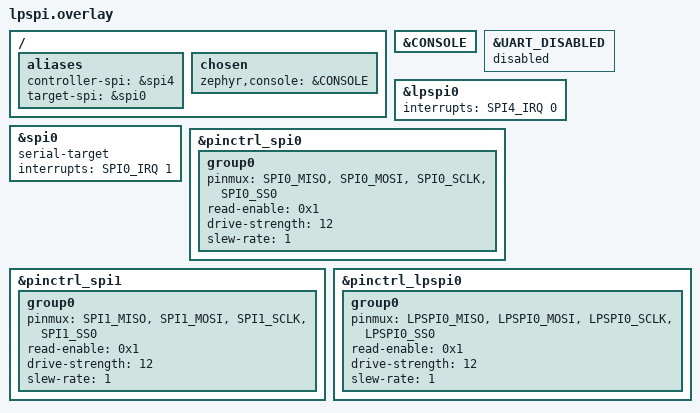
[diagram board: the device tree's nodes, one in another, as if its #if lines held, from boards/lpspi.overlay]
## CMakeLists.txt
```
cmake_minimum_required(VERSION 3.20.0)

# ==================== BOARD OVERRIDE (optional) ==================
# ALIF_BOARD is auto-detected in board_common.overlay from Zephyr
# Kconfig symbols (CONFIG_SOC_SERIES_* / CONFIG_RTSS_*).
# To override manually: west build -b <board> -- -DALIF_BOARD=ALIF_BOARD_E7_HP
if(DEFINED ALIF_BOARD)
  list(APPEND DTS_EXTRA_CPPFLAGS "-DALIF_BOARD=${ALIF_BOARD}")
  message(STATUS "SPI test overlay board (manual override): ${ALIF_BOARD}")
endif()

# ==================== ZEPHYR PROJECT SETUP ==================
find_package(Zephyr REQUIRED HINTS $ENV{ZEPHYR_BASE})
project(alif_spi)

# ==================== STACK SIZES ==========================
# Stack sizes are defined in prj.conf (20KB default for all tests)

target_include_directories(app PRIVATE src)

# ==================== SOURCE FILES ==========================
target_sources(app PRIVATE
  src/test_spi_common.c
  src/test_spi_threads.c
)

target_sources_ifdef(CONFIG_TEST_SPI_LOOPBACK    app PRIVATE src/test_spi_loopback.c)
target_sources_ifdef(CONFIG_TEST_SPI_NEGATIVE   app PRIVATE src/test_spi_negative.c)
target_sources_ifdef(CONFIG_TEST_SPI_BOUNDARY   app PRIVATE src/test_spi_boundary.c)
target_sources_ifdef(CONFIG_TEST_SPI_STRESS     app PRIVATE src/test_spi_stress.c)
target_sources_ifdef(CONFIG_TEST_SPI_PERFORMANCE app PRIVATE src/test_spi_perf.c)

# ==================== COMPILATION FLAGS ======================
if(CMAKE_BUILD_TYPE STREQUAL "Debug")
  target_compile_options(app PRIVATE -Wall -Wextra -Werror)
endif()

# ==================== VALIDATION MESSAGES ====================
message(STATUS "  Test Type: SPI Driver Validation")
message(STATUS "  Hardware Overlay: ${DTC_OVERLAY_FILE}")

if(CONFIG_TEST_SPI_LOOPBACK)
  message(STATUS "  Enabled: Loopback Tests")
endif()

if(CONFIG_TEST_SPI_NEGATIVE)
  message(STATUS "  Enabled: Negative Tests")
endif()

if(CONFIG_TEST_SPI_BOUNDARY)
  message(STATUS "  Enabled: Boundary Tests")
endif()

if(CONFIG_TEST_SPI_STRESS)
  message(STATUS "  Enabled: Stress Tests")
endif()

if(CONFIG_TEST_SPI_PERFORMANCE)
  message(STATUS "  Enabled: Performance Tests")
endif()

if(CONFIG_TEST_SPI_USE_DMA)
  message(STATUS "  Enabled: DMA path")
endif()
```

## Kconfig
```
source "Kconfig.zephyr"

# ---------------------------------------------------------------------------
# Test selection - enable the test you want to run
# ---------------------------------------------------------------------------

config TEST_SPI_LOOPBACK
	bool "Loopback tests"
	help
	  Enable the SPI loopback test suite.  This suite exercises
	  the controller by wiring MOSI to MISO either internally or
	  externally and validates data integrity across 8, 16 and
	  32-bit word sizes at configurable frequencies.

config TEST_SPI_NEGATIVE
	bool "Negative tests"
	help
	  Enable the SPI negative test suite.  These tests deliberately
	  pass invalid configurations, unsupported SPI modes, and null
	  pointers to the driver to verify that proper error codes are
	  returned and the driver does not crash or corrupt state.

config TEST_SPI_BOUNDARY
	bool "Boundary tests"
	help
	  Enable the SPI boundary test suite.  These tests probe driver
	  behaviour at FIFO depth limits, minimum and maximum transfer
	  sizes, unaligned buffer addresses, and extreme word widths
	  to ensure robust handling of edge cases.

config TEST_SPI_STRESS
	bool "Stress tests"
	help
	  SPI stress tests that exercise repeated back-to-back
	  full-duplex transfers between two controllers (SPI1 <-> SPI0)
	  with rotating data patterns. Detects FIFO leakage and
	  state retention issues across iterations.

config TEST_SPI_PERFORMANCE
	bool "Performance tests"
	help
	  Enable the SPI performance test suite.  It runs back-to-back
	  MOSI, MISO and full-duplex transceive tests while sweeping the
	  frequency from TEST_SPI_PERF_FREQ_MIN_MHZ to
	  TEST_SPI_PERF_FREQ_MAX_MHZ (defaults 1x..50x the base rate) in
	  TEST_SPI_PERF_FREQ_STEP_MHZ increments, reporting cycle counts
	  and elapsed time.

# ---------------------------------------------------------------------------
# Performance sweep range (multipliers of TEST_SPI_FREQUENCY)
# ---------------------------------------------------------------------------

config TEST_SPI_PERF_FREQ_MIN_MHZ
	int "Performance sweep start frequency (x base)"
	depends on TEST_SPI_PERFORMANCE
	default 1
	help
	  First frequency multiplier of the performance sweep, in units
	  of TEST_SPI_FREQUENCY (default base 1 MHz).  With the default
	  base of 1 MHz this is the start frequency in MHz.

config TEST_SPI_PERF_FREQ_MAX_MHZ
	int "Performance sweep end frequency (x base)"
	depends on TEST_SPI_PERFORMANCE
	default 5
	help
	  Last frequency multiplier of the performance sweep, in units
	  of TEST_SPI_FREQUENCY (default base 1 MHz).  With the default
	  base of 1 MHz this is the end frequency in MHz.

config TEST_SPI_PERF_FREQ_STEP_MHZ
	int "Performance sweep step (x base)"
	depends on TEST_SPI_PERFORMANCE
	range 1 5
	default 1
	help
	  Increment between consecutive sweep points, in units of
	  TEST_SPI_FREQUENCY.  The endpoint TEST_SPI_PERF_FREQ_MAX_MHZ is
	  always tested even if it does not fall on a step boundary.

# ---------------------------------------------------------------------------
# Test options
# ---------------------------------------------------------------------------

config TEST_SPI_INTERNAL_LOOPBACK
	bool "Use controller internal loopback for loopback and boundary tests"
	depends on TEST_SPI_LOOPBACK || TEST_SPI_BOUNDARY
	default y
	help
	  When enabled, loopback and boundary tests run on a single
	  controller using the SPI_MODE_LOOP flag (no external wiring
	  needed). When disabled, the same tests run across two
	  controllers (SPI1 as controller, SPI0 as target wired
	  together) and validate both MOSI and MISO directions
	  with two independent transceives.

config TEST_SPI_WORD_SIZE
	int "SPI word size for all tests"
	range 4 32
	default 8
	help
	  Fixed word size (4..32 bits) used by all test suites.

config TEST_SPI_FREQUENCY
	int "SPI test base frequency (Hz)"
	default 1000000
	help
	  Base operating frequency used by all SPI test scenarios.
	  Frequency sweep multipliers (1x, 5x, 12x, 25x) and the
	  performance sweep are relative to this value.  Default is
	  1 MHz (1000000 Hz).

# ---------------------------------------------------------------------------
# DMA support
# ---------------------------------------------------------------------------
config TEST_SPI_USE_DMA
	bool "Enable DMA for SPI transfers"
	depends on $(dt_nodelabel_enabled,dma0) || $(dt_nodelabel_enabled,dma1) || $(dt_nodelabel_enabled,dma2)
	select SPI_DW_USE_DMA
	select DMA
	select DMA_PL330
	help
	  Enable DMA-based SPI transfers for all selected test suites.
	  When enabled, the driver routes large transfers through the
	  PL330 DMA controller instead of the PIO path.  This option is
	  only selectable when a DMA controller node is present in the
	  active devicetree overlay (e.g. spi_DMA.overlay).
```

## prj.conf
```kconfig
# Note: SPI slave mode (target role) enabled
# Base SPI driver
CONFIG_SPI=y
CONFIG_SPI_DW=y
CONFIG_SPI_SLAVE=y

# Zephyr test framework
CONFIG_ZTEST=y


CONFIG_LOG=y
CONFIG_LOG_DEFAULT_LEVEL=1

# Kernel features
CONFIG_EVENTS=y
CONFIG_STDOUT_CONSOLE=y

# Async SPI path coverage (sync path uses spi_transceive, async uses
# spi_transceive_signal which needs both of these)
CONFIG_SPI_ASYNC=y
CONFIG_POLL=y

# Stack sizes - stress tests need larger stacks
CONFIG_MAIN_STACK_SIZE=20480
CONFIG_ZTEST_STACK_SIZE=20480
```

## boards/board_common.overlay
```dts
/* Copyright (C) 2025 Alif Semiconductor - All Rights Reserved.
 * Use, distribution and modification of this code is permitted under the
 * terms stated in the Alif Semiconductor Software License Agreement
 *
 * You should have received a copy of the Alif Semiconductor Software
 * License Agreement with this file. If not, please write to:
 * contact@alifsemi.com, or visit: https://alifsemi.com/license
 */

/*
 * -----------------------------------------------------------------------
 * Alif SPI test board-common macros.
 *
 * Include this from every instance/feature overlay:
 *   #include "board_common.overlay"
 *
 * It defines board-specific pinmux, interrupt numbers, GPIO/SS mappings,
 * console choice and DMA controller — everything that varies by board.
 *
 * Instance overlays then only need to:
 *   - pick controller-spi / target-spi aliases
 *   - &node { status = "okay"; interrupts = <ALIF_SPIx_IRQ 0>; };
 *   - apply &pinctrl using the ALIF_SPIx_* macros from this file.
 * -----------------------------------------------------------------------
 */

#ifndef ALIF_BOARD_COMMON_OVERLAY
#define ALIF_BOARD_COMMON_OVERLAY

/* --- Board enum ------------------------------------------------------- */
#define ALIF_BOARD_E7_HP 1
#define ALIF_BOARD_E8_HP 2
#define ALIF_BOARD_E7_HE 3
#define ALIF_BOARD_E8_HE 4
#define ALIF_BOARD_E1C   5
#define ALIF_BOARD_B1    6

/* Manual override: -DALIF_BOARD=ALIF_BOARD_E7_HP on west command line  */
#ifndef ALIF_BOARD
#define ALIF_BOARD ALIF_BOARD_E8_HP
#endif

/* --- Console (UART) --------------------------------------------------- */
#if ALIF_BOARD == ALIF_BOARD_E7_HP || ALIF_BOARD == ALIF_BOARD_E8_HP
  #define CONSOLE          uart4
  #define UART_DISABLED    uart2
#else
  #define CONSOLE          lpuart
  #define UART_DISABLED    uart2
#endif

/* --- SPI0 pinmux ------------------------------------------------------ */
#if ALIF_BOARD == ALIF_BOARD_E1C || ALIF_BOARD == ALIF_BOARD_B1
  #define SPI0_MISO   PIN_P5_0__SPI0_MISO_B
  #define SPI0_MOSI   PIN_P5_1__SPI0_MOSI_B
  #define SPI0_SCLK   PIN_P5_2__SPI0_SCLK_B
  #define SPI0_SS0    PIN_P5_3__SPI0_SS0_B
#elif ALIF_BOARD == ALIF_BOARD_E7_HP || ALIF_BOARD == ALIF_BOARD_E7_HE
  #define SPI0_MISO   PIN_P5_0__SPI0_MISO_B
  #define SPI0_MOSI   PIN_P5_1__SPI0_MOSI_B
  #define SPI0_SCLK   PIN_P5_3__SPI0_SCLK_B
  #define SPI0_SS0    PIN_P5_2__SPI0_SS0_B
#else
  #define SPI0_MISO   PIN_P1_0__SPI0_MISO_A
  #define SPI0_MOSI   PIN_P1_1__SPI0_MOSI_A
  #define SPI0_SCLK   PIN_P1_2__SPI0_SCLK_A
  #define SPI0_SS0    PIN_P1_3__SPI0_SS0_A
#endif

/* --- SPI1 pinmux ------------------------------------------------------ */
#if ALIF_BOARD == ALIF_BOARD_E7_HP || ALIF_BOARD == ALIF_BOARD_E7_HE
  #define SPI1_MISO   PIN_P8_3__SPI1_MISO_B
  #define SPI1_MOSI   PIN_P8_4__SPI1_MOSI_B
  #define SPI1_SCLK   PIN_P8_5__SPI1_SCLK_B
  #define SPI1_SS0    PIN_P6_4__SPI1_SS0_B
#elif ALIF_BOARD == ALIF_BOARD_E8_HP || ALIF_BOARD == ALIF_BOARD_E8_HE
  #define SPI1_MISO   PIN_P14_4__SPI1_MISO_C
  #define SPI1_MOSI   PIN_P14_5__SPI1_MOSI_C
  #define SPI1_SCLK   PIN_P14_6__SPI1_SCLK_C
  #define SPI1_SS0    PIN_P14_7__SPI1_SS0_C
#elif ALIF_BOARD == ALIF_BOARD_E1C || ALIF_BOARD == ALIF_BOARD_B1
  #define SPI1_MISO   PIN_P8_4__SPI1_MISO_C
  #define SPI1_MOSI   PIN_P8_5__SPI1_MOSI_C
  #define SPI1_SCLK   PIN_P8_6__SPI1_SCLK_C
  #define SPI1_SS0    PIN_P8_7__SPI1_SS0_C
#endif

/* --- SPI2 pinmux ------------------------------------------------------ */
#if ALIF_BOARD == ALIF_BOARD_E1C || ALIF_BOARD == ALIF_BOARD_B1
  #define SPI2_MISO   PIN_P7_0__SPI2_MISO_B
  #define SPI2_MOSI   PIN_P7_1__SPI2_MOSI_B
  #define SPI2_SCLK   PIN_P7_2__SPI2_SCLK_B
  #define SPI2_SS0    PIN_P7_3__SPI2_SS0_B
#else
  #define SPI2_MISO   PIN_P4_2__SPI2_MISO_A
  #define SPI2_MOSI   PIN_P4_3__SPI2_MOSI_A
  #define SPI2_SCLK   PIN_P4_4__SPI2_SCLK_A
  #define SPI2_SS0    PIN_P4_5__SPI2_SS0_A
#endif

/* --- SPI3 pinmux ------------------------------------------------------ */
#if ALIF_BOARD == ALIF_BOARD_E7_HP || \
	ALIF_BOARD == ALIF_BOARD_E7_HE
  #define SPI3_MISO   PIN_P10_5__SPI3_MISO_B
  #define SPI3_MOSI   PIN_P12_5__SPI3_MOSI_A
  #define SPI3_SCLK   PIN_P12_6__SPI3_SCLK_B
  #define SPI3_SS0    PIN_P12_7__SPI3_SS0_B
#elif ALIF_BOARD == ALIF_BOARD_E8_HP || \
	ALIF_BOARD == ALIF_BOARD_E8_HE
  #define SPI3_MISO   PIN_P12_4__SPI3_MISO_A
  #define SPI3_MOSI   PIN_P12_5__SPI3_MOSI_A
  #define SPI3_SCLK   PIN_P12_6__SPI3_SCLK_A
  #define SPI3_SS0    PIN_P12_7__SPI3_SS0_A
#endif

/* --- SPI4 / LPSPI0 pinmux (HE boards) -------------------------- */
#if ALIF_BOARD == ALIF_BOARD_E7_HE
  #define SPI4_MISO   PIN_P7_4__LPSPI_MISO_A
  #define SPI4_MOSI   PIN_P7_5__LPSPI_MOSI_A
  #define SPI4_SCLK   PIN_P7_6__LPSPI_SCLK_A
  #define SPI4_SS0    PIN_P7_7__LPSPI_SS_A
#elif ALIF_BOARD == ALIF_BOARD_E8_HE
  #define SPI4_MISO   PIN_P11_4__LPSPI_MISO_B
  #define SPI4_MOSI   PIN_P11_5__LPSPI_MOSI_B
  #define SPI4_SCLK   PIN_P11_6__LPSPI_SCLK_B
  #define SPI4_SS0    PIN_P11_7__LPSPI_SS0_B
#elif ALIF_BOARD == ALIF_BOARD_E1C || ALIF_BOARD == ALIF_BOARD_B1
  #define LPSPI0_MISO PIN_P1_3__LPSPI_MISO_A
  #define LPSPI0_MOSI PIN_P1_4__LPSPI_MOSI_A
  #define LPSPI0_SCLK PIN_P1_5__LPSPI_SCLK_A
  #define LPSPI0_SS0  PIN_P2_0__LPSPI_SS_A
#endif

/* --- Interrupt numbers (instance-based, same across boards) ---------- */
#define SPI0_IRQ    137
#define SPI1_IRQ    138
#define SPI2_IRQ    139
#define SPI3_IRQ    140
#define SPI4_IRQ    46   /* LPSPI0 interrupt number */

/* --- Software-CS GPIO pins (SPI1-based overlays) --------------------- */
#if ALIF_BOARD == ALIF_BOARD_E7_HP || ALIF_BOARD == ALIF_BOARD_E7_HE
  #define SPI_SS_GPIO_PIN   PIN_P6_4__GPIO
  #define SPI_SS_GPIO_BANK  gpio6
  #define SPI_SS_GPIO_NUM   4
#elif ALIF_BOARD == ALIF_BOARD_E8_HP || ALIF_BOARD == ALIF_BOARD_E8_HE
  #define SPI_SS_GPIO_PIN   PIN_P14_7__GPIO
  #define SPI_SS_GPIO_BANK  gpio14
  #define SPI_SS_GPIO_NUM   7
#elif ALIF_BOARD == ALIF_BOARD_E1C || ALIF_BOARD == ALIF_BOARD_B1
  #define SPI_SS_GPIO_PIN   PIN_P8_7__GPIO
  #define SPI_SS_GPIO_BANK  gpio8
  #define SPI_SS_GPIO_NUM   7
#endif

/* --- Software-CS GPIO pins (LPSPI-based overlays) --------------------- */
#if ALIF_BOARD == ALIF_BOARD_E7_HE
  #define LPSPI_SS_GPIO_PIN   PIN_P7_7__GPIO
  #define LPSPI_SS_GPIO_BANK  gpio7
  #define LPSPI_SS_GPIO_NUM   7
#elif ALIF_BOARD == ALIF_BOARD_E8_HE
  #define LPSPI_SS_GPIO_PIN   PIN_P11_7__GPIO
  #define LPSPI_SS_GPIO_BANK  gpio11
  #define LPSPI_SS_GPIO_NUM   7
#elif ALIF_BOARD == ALIF_BOARD_E1C || ALIF_BOARD == ALIF_BOARD_B1
  #define LPSPI_SS_GPIO_PIN   PIN_P2_0__GPIO
  #define LPSPI_SS_GPIO_BANK  gpio2
  #define LPSPI_SS_GPIO_NUM   0
#endif

/* --- DMA controller for SPI0/SPI1 ---------------------------------- */
#if ALIF_BOARD == ALIF_BOARD_E1C || ALIF_BOARD == ALIF_BOARD_B1
  #define SPI_DMA          dma2
  #define SPI_DMA_EVTRTR   evtrtr2
#else
  #define SPI_DMA          dma0
  #define SPI_DMA_EVTRTR   evtrtr0
#endif

#endif /* ALIF_BOARD_COMMON_OVERLAY */
```

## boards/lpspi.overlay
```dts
/* Copyright (C) 2025 Alif Semiconductor - All Rights Reserved.
 * Use, distribution and modification of this code is permitted under the
 * terms stated in the Alif Semiconductor Software License Agreement
 *
 * You should have received a copy of the Alif Semiconductor Software
 * License Agreement with this file. If not, please write to:
 * contact@alifsemi.com, or visit: https://alifsemi.com/license
 */

/* LPSPI / SPI test overlay.
 * HE: SPI4 controller <-> SPI0/SPI1 target (board-dependent)
 * E1C/B1: LPSPI0 controller <-> SPI1 target
 */
#include "board_common.overlay"

/ {
	aliases {
#if ALIF_BOARD == ALIF_BOARD_E7_HE
		controller-spi = &spi4;
		target-spi     = &spi0;
#elif ALIF_BOARD == ALIF_BOARD_E8_HE
		controller-spi = &spi4;
		target-spi     = &spi1;
#elif ALIF_BOARD == ALIF_BOARD_E1C || ALIF_BOARD == ALIF_BOARD_B1
		controller-spi = &lpspi0;
		target-spi     = &spi1;
#else
		/* Default to SPI4/SPI0 for unknown HE boards */
		controller-spi = &spi4;
		target-spi     = &spi0;
#endif
	};

	chosen {
		zephyr,console = &CONSOLE;
	};
};

&CONSOLE {
	status = "okay";
};

&UART_DISABLED {
	status = "disabled";
};

#if ALIF_BOARD == ALIF_BOARD_E1C || ALIF_BOARD == ALIF_BOARD_B1
&lpspi0 {
	status = "okay";
	interrupts = <SPI4_IRQ 0>;
};
#else
&spi4 {
	status = "okay";
	interrupts = <SPI4_IRQ 0>;
};
#endif

#if ALIF_BOARD == ALIF_BOARD_E7_HE
&spi0 {
	status = "okay";
	serial-target;
	interrupts = <SPI0_IRQ 1>;
};
#else
&spi1 {
	status = "okay";
	serial-target;
	interrupts = <SPI1_IRQ 1>;
};
#endif

#if ALIF_BOARD == ALIF_BOARD_E7_HE
&pinctrl_spi0 {
	group0 {
		pinmux = < SPI0_MISO >,
			 < SPI0_MOSI >,
			 < SPI0_SCLK >,
			 < SPI0_SS0 >;
		read-enable = < 0x1 >;
		drive-strength = < 12 >;
		slew-rate = < 1 >;
	};
};
#endif

#if ALIF_BOARD != ALIF_BOARD_E7_HE
&pinctrl_spi1 {
	group0 {
		pinmux = < SPI1_MISO >,
			 < SPI1_MOSI >,
			 < SPI1_SCLK >,
			 < SPI1_SS0 >;
		read-enable = < 0x1 >;
		drive-strength = < 12 >;
		slew-rate = < 1 >;
	};
};
#endif

#if ALIF_BOARD == ALIF_BOARD_E1C || ALIF_BOARD == ALIF_BOARD_B1
&pinctrl_lpspi0 {
	group0 {
		pinmux = < LPSPI0_MISO >,
			 < LPSPI0_MOSI >,
			 < LPSPI0_SCLK >,
			 < LPSPI0_SS0 >;
		read-enable = < 0x1 >;
		drive-strength = < 12 >;
		slew-rate = < 1 >;
	};
};
#else
&pinctrl_lpspi {
	group0 {
		pinmux = < SPI4_MISO >,
			 < SPI4_MOSI >,
			 < SPI4_SCLK >,
			 < SPI4_SS0 >;
		read-enable = < 0x1 >;
		drive-strength = < 12 >;
		slew-rate = < 1 >;
	};
};
#endif
```

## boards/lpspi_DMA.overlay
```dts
/* Copyright (C) 2025 Alif Semiconductor - All Rights Reserved.
 * Use, distribution and modification of this code is permitted under the
 * terms stated in the Alif Semiconductor Software License Agreement
 *
 * You should have received a copy of the Alif Semiconductor Software
 * License Agreement with this file. If not, please write to:
 * contact@alifsemi.com, or visit: https://alifsemi.com/license
 */

/* DMA overlay for LPSPI test instances.  Stack with boards/lpspi.overlay.
 * spi4/lpspi0 uses dma2; spi0/spi1 uses dma0.
 */
#include "board_common.overlay"

&dma0 {
	status = "okay";
};

&dma2 {
	status = "okay";
};

#if ALIF_BOARD == ALIF_BOARD_E1C || ALIF_BOARD == ALIF_BOARD_B1
&lpspi0 {
	dmas = <&dma2 0 13>, <&dma2 1 12>;
	dma-names = "txdma", "rxdma";
};
#else
&spi4 {
	dmas = <&dma2 0 13>, <&dma2 1 12>;
	dma-names = "txdma", "rxdma";
};
#endif

#if ALIF_BOARD == ALIF_BOARD_E7_HE
&spi0 {
	dmas = <&dma0 2 20>, <&dma0 3 16>;
	dma-names = "txdma", "rxdma";
};
#else
&spi1 {
	dmas = <&dma0 2 21>, <&dma0 3 17>;
	dma-names = "txdma", "rxdma";
};
#endif
```

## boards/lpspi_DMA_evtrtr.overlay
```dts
/* Copyright (C) 2025 Alif Semiconductor - All Rights Reserved.
 * Use, distribution and modification of this code is permitted under the
 * terms stated in the Alif Semiconductor Software License Agreement
 *
 * You should have received a copy of the Alif Semiconductor Software
 * License Agreement with this file. If not, please write to:
 * contact@alifsemi.com, or visit: https://alifsemi.com/license
 */

/* Event-router DMA overlay for LPSPI instances.
 * Stack with boards/lpspi.overlay.
 * LPSPI is HE-only, uses dma2 and evtrtr2.
 */
#include <zephyr/dt-bindings/dma/alif_dma_event_router.h>
#include "board_common.overlay"

&dma2 {
	status = "okay";
};

&evtrtr2 {
	status = "okay";
};

#if ALIF_BOARD == ALIF_BOARD_E1C || ALIF_BOARD == ALIF_BOARD_B1
&lpspi0 {
	dmas = <&evtrtr2 ALIF_DMA_ENCODE(0, 2, 1) 13>,
	       <&evtrtr2 ALIF_DMA_ENCODE(1, 2, 1) 12>;
	dma-names = "txdma", "rxdma";
};
#else
&spi4 {
	dmas = <&evtrtr2 ALIF_DMA_ENCODE(0, 2, 1) 13>,
	       <&evtrtr2 ALIF_DMA_ENCODE(1, 2, 1) 12>;
	dma-names = "txdma", "rxdma";
};
#endif

#if ALIF_BOARD == ALIF_BOARD_E7_HE
&spi0 {
	dmas = <&evtrtr2 ALIF_DMA_ENCODE(2, 2, 1) 20>,
	       <&evtrtr2 ALIF_DMA_ENCODE(3, 2, 1) 16>;
	dma-names = "txdma", "rxdma";
};
#else
&spi1 {
	dmas = <&evtrtr2 ALIF_DMA_ENCODE(2, 2, 1) 21>,
	       <&evtrtr2 ALIF_DMA_ENCODE(3, 2, 1) 17>;
	dma-names = "txdma", "rxdma";
};
#endif
```

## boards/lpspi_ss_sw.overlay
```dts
/* Copyright (C) 2025 Alif Semiconductor - All Rights Reserved.
 * Use, distribution and modification of this code is permitted under the
 * terms stated in the Alif Semiconductor Software License Agreement
 *
 * You should have received a copy of the Alif Semiconductor Software
 * License Agreement with this file. If not, please write to:
 * contact@alifsemi.com, or visit: https://alifsemi.com/license
 */

/* Software-CS overlay for LPSPI controller.
 * Stack with boards/lpspi.overlay.
 */
#include "board_common.overlay"

#if ALIF_BOARD == ALIF_BOARD_E1C || ALIF_BOARD == ALIF_BOARD_B1
&lpspi0 {
	status = "okay";
	cs-gpios = <&LPSPI_SS_GPIO_BANK LPSPI_SS_GPIO_NUM GPIO_ACTIVE_LOW>;
	interrupts = <SPI4_IRQ 0>;
};

&pinctrl_lpspi0 {
	group0 {
		pinmux = < LPSPI0_MISO >,
			 < LPSPI0_MOSI >,
			 < LPSPI0_SCLK >,
			 < LPSPI_SS_GPIO_PIN >;
		read-enable = < 0x1 >;
		drive-strength = < 12 >;
		slew-rate = < 1 >;
	};
};
#else
&spi4 {
	status = "okay";
	cs-gpios = <&LPSPI_SS_GPIO_BANK LPSPI_SS_GPIO_NUM GPIO_ACTIVE_LOW>;
	interrupts = <SPI4_IRQ 0>;
};

&pinctrl_lpspi {
	group0 {
		pinmux = < SPI4_MISO >,
			 < SPI4_MOSI >,
			 < SPI4_SCLK >,
			 < LPSPI_SS_GPIO_PIN >;
		read-enable = < 0x1 >;
		drive-strength = < 12 >;
		slew-rate = < 1 >;
	};
};
#endif

&LPSPI_SS_GPIO_BANK {
	status = "okay";
};
```

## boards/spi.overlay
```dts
/* Copyright (C) 2025 Alif Semiconductor - All Rights Reserved.
 * Use, distribution and modification of this code is permitted under the
 * terms stated in the Alif Semiconductor Software License Agreement
 *
 * You should have received a copy of the Alif Semiconductor Software
 * License Agreement with this file. If not, please write to:
 * contact@alifsemi.com, or visit: https://alifsemi.com/license
 */

/* SPI0/SPI1 test overlay.  Include board-common macros then wire SPI1
 * controller <-> SPI0 target.  Board is auto-detected from the BOARD
 * CMake variable (set in CMakeLists.txt) or can be overridden on the
 * west command line with -DALIF_BOARD=ALIF_BOARD_E7_HP.
 */
#include "board_common.overlay"

/ {
	aliases {
		controller-spi = &spi1;
		target-spi     = &spi0;
	};

	chosen {
		zephyr,console = &CONSOLE;
	};
};

&CONSOLE {
	status = "okay";
};

&UART_DISABLED {
	status = "disabled";
};

&spi1 {
	status = "okay";
	interrupts = <SPI1_IRQ 0>;
	/* Controller samples MISO. At high SCLK the round-trip
	 * (SCLK out -> target -> MISO back) exceeds one bit period,
	 * so delay the RX sample point. Tune this for the test freq.
	 * Units: ssi_clk (HCLK = 200 MHz) cycles. Default in DTS is 4.
	 */
	/*rx-delay = <8>;*/
};

&spi0 {
	status = "okay";
	serial-target;
	interrupts = <SPI0_IRQ 1>;
	/* Same-chip target RX at 50 MHz: sample on the clock edge
	 * (no additional delay).  Default rx-delay=4 is too late.
	 */
	/*rx-delay = <0>;*/
};

&pinctrl_spi0 {
	group0 {
		pinmux = < SPI0_MISO >,
			 < SPI0_MOSI >,
			 < SPI0_SCLK >,
			 < SPI0_SS0 >;
		read-enable = < 0x1 >;
		drive-strength = < 12 >;
		slew-rate = < 1 >;
	};
};

&pinctrl_spi1 {
	group0 {
		pinmux = < SPI1_MISO >,
			 < SPI1_MOSI >,
			 < SPI1_SCLK >,
			 < SPI1_SS0 >;
		read-enable = < 0x1 >;
		drive-strength = < 12 >;
		slew-rate = < 1 >;
	};
};
```

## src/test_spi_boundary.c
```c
/* Copyright Alif Semiconductor - All Rights Reserved.
 * Use, distribution and modification of this code is permitted under the
 * terms stated in the Alif Semiconductor Software License Agreement
 *
 * You should have received a copy of the Alif Semiconductor Software
 * License Agreement with this file. If not, please write to:
 * contact@alifsemi.com, or visit: https://alifsemi.com/license
 */

/*
 * Alif SPI boundary / edge-case validation suite.
 *
 * Two ZTESTs only:
 *   - test_boundary_sync  : runs the boundary scenarios using
 *                           synchronous spi_transceive
 *   - test_boundary_async : same scenarios driven via
 *                           spi_transceive_signal + k_poll
 */

#include <zephyr/kernel.h>
#include <zephyr/drivers/spi.h>
#include <zephyr/ztest.h>
#include <zephyr/logging/log.h>

#if IS_ENABLED(CONFIG_TEST_SPI_BOUNDARY)

#include "test_spi_common.h"

LOG_MODULE_REGISTER(spi_test_bnd, LOG_LEVEL_INF);

#define BND_MAX_BUF           1024
#define BND_DEFAULT_FREQ      SPI_FREQ_MHZ

static const struct device *const controller_dev =
	DEVICE_DT_GET(SPI_CONTROLLER_NODE);

static struct k_poll_signal bnd_async_sig;
static struct k_poll_event  bnd_async_evt;

static int bnd_xfer(const struct spi_config *cfg,
		    const struct spi_buf_set *tx,
		    const struct spi_buf_set *rx,
		    bool async)
{
	int ret;
	size_t tx_len = 0U;
	size_t rx_len = 0U;

	if (!async) {
		return spi_transceive(controller_dev, cfg, tx, rx);
	}

	k_poll_signal_reset(&bnd_async_sig);
	bnd_async_evt.signal->signaled = 0U;
	bnd_async_evt.state = K_POLL_STATE_NOT_READY;

	ret = spi_transceive_signal(controller_dev, cfg, tx, rx, &bnd_async_sig);
	if (ret != 0) {
		return ret;
	}

	if ((tx != NULL) && (tx->buffers != NULL)) {
		for (size_t i = 0U; i < tx->count; i++) {
			tx_len += tx->buffers[i].len;
		}
	}
	if ((rx != NULL) && (rx->buffers != NULL)) {
		for (size_t i = 0U; i < rx->count; i++) {
			rx_len += rx->buffers[i].len;
		}
	}

	ret = k_poll(&bnd_async_evt, 1,
		     spi_test_transfer_timeout(MAX(tx_len, rx_len),
					       cfg->frequency));
	if (ret != 0) {
		LOG_ERR("boundary async poll timeout @%u Hz", cfg->frequency);
		return -ETIMEDOUT;
	}
	return bnd_async_sig.result;
}

static int bnd_xfer_compare(const struct spi_config *cfg,
			    void *tx, void *rx, size_t len, bool async)
{
	struct spi_buf tb = { .buf = tx, .len = len };
	struct spi_buf rb = { .buf = rx, .len = len };
	struct spi_buf_set ts = { .buffers = &tb, .count = 1 };
	struct spi_buf_set rs = { .buffers = &rb, .count = 1 };
	int ret;

	memset(rx, 0, len);
	ret = bnd_xfer(cfg, &ts, &rs, async);
	if (ret < 0) {
		return ret;
	}
	return memcmp(tx, rx, len) == 0 ? 0 : -EIO;
}

static struct spi_config bnd_cfg(uint32_t word, uint32_t freq_hz)
{
	uint32_t operation = SPI_OP_MODE_MASTER | SPI_WORD_SET(word);

	if (IS_ENABLED(CONFIG_TEST_SPI_INTERNAL_LOOPBACK)) {
		operation |= SPI_MODE_LOOP;
	}
	return spi_test_config(operation, freq_hz);
}

static int sc_single_byte(bool async)
{
	static const uint8_t patterns[] = {
		0x00, 0xFF, 0xA5, 0x5A, 0x01, 0xFE, 0x55, 0xAA
	};
	struct spi_config cfg = bnd_cfg(8U, BND_DEFAULT_FREQ);
	int fail = 0;

	for (size_t p = 0; p < ARRAY_SIZE(patterns); p++) {
		uint8_t tx = patterns[p];
		uint8_t rx = 0U;
		int ret = bnd_xfer_compare(&cfg, &tx, &rx, 1U, async);

		if (ret != 0) {
			LOG_ERR("single_byte 0x%02X ret=%d", patterns[p], ret);
			fail++;
		}
	}
	return fail;
}

static int sc_fifo_sizes(uint32_t word, const size_t *sizes,
			 size_t n_sizes, bool async)
{
	static uint32_t tx[64];
	static uint32_t rx[64];
	struct spi_config cfg = bnd_cfg(word, BND_DEFAULT_FREQ);
	int fail = 0;
	size_t bytes_per_frame = word / 8U;

	for (size_t s = 0; s < n_sizes; s++) {
		size_t frames = sizes[s];
		size_t len = frames * bytes_per_frame;

		for (size_t i = 0; i < ARRAY_SIZE(tx); i++) {
			tx[i] = 0xA5000000U | (uint32_t)(i + frames);
		}
		int ret = bnd_xfer_compare(&cfg, tx, rx, len, async);

		if (ret != 0) {
			LOG_ERR("fifo_%u_bit frames=%zu ret=%d", word,
				frames, ret);
			fail++;
		}
	}
	return fail;
}

static int sc_fifo_8bit(bool async)
{
	static const size_t sizes[] = {15, 16, 17, 31, 32, 33, 63, 64, 65};

	return sc_fifo_sizes(8U, sizes, ARRAY_SIZE(sizes), async);
}

static int sc_fifo_16bit(bool async)
{
	static const size_t sizes[] = {15, 16, 17, 31, 32, 33};

	return sc_fifo_sizes(16U, sizes, ARRAY_SIZE(sizes), async);
}

static int sc_fifo_32bit(bool async)
{
	static const size_t sizes[] = {15, 16, 17, 31, 32, 33};

	return sc_fifo_sizes(32U, sizes, ARRAY_SIZE(sizes), async);
}

static int sc_fifo_flush(bool async)
{
	struct spi_config cfg = bnd_cfg(8U, BND_DEFAULT_FREQ);
	uint8_t tx_a[17], rx_a[17];
	uint8_t tx_b[17], rx_b[17];
	int ret;

	memset(tx_a, 0xA5, sizeof(tx_a));
	for (size_t i = 0; i < sizeof(tx_b); i++) {
		tx_b[i] = (uint8_t)(i & 0xFFU);
	}

	ret = bnd_xfer_compare(&cfg, tx_a, rx_a, sizeof(tx_a), async);
	if (ret != 0) {
		LOG_ERR("fifo_flush A ret=%d", ret);
		return 1;
	}
	ret = bnd_xfer_compare(&cfg, tx_b, rx_b, sizeof(tx_b), async);
	if (ret != 0) {
		LOG_ERR("fifo_flush B (stale data?) ret=%d", ret);
		return 1;
	}
	return 0;
}

static int sc_xfer_sweep(bool async)
{
	static const size_t sizes[] = {1, 2, 4, 8, 16, 32, 64, 128, 256};
	static const uint8_t pat[] = {0xDE, 0xAD, 0xBE, 0xEF};
	static uint8_t tx[256], rx[256];
	struct spi_config cfg = bnd_cfg(8U, BND_DEFAULT_FREQ);
	int fail = 0;

	for (size_t s = 0; s < ARRAY_SIZE(sizes); s++) {
		size_t len = sizes[s];

		for (size_t i = 0; i < len; i++) {
			tx[i] = pat[i & 3U];
		}
		int ret = bnd_xfer_compare(&cfg, tx, rx, len, async);

		if (ret != 0) {
			LOG_ERR("xfer_sweep len=%zu ret=%d", len, ret);
			fail++;
		}
	}
	return fail;
}

static int sc_fifo_plus_one(bool async)
{
	struct spi_config cfg = bnd_cfg(8U, BND_DEFAULT_FREQ);
	uint8_t tx[33], rx[33];

	for (size_t i = 0; i < sizeof(tx); i++) {
		tx[i] = (uint8_t)(i + 1U);
	}
	int ret = bnd_xfer_compare(&cfg, tx, rx, sizeof(tx), async);

	if (ret != 0) {
		LOG_ERR("fifo_plus_one ret=%d", ret);
		return 1;
	}
	return 0;
}

static int sc_large_xfer(bool async)
{
	struct spi_config cfg = bnd_cfg(8U, BND_DEFAULT_FREQ);
	static uint8_t tx[BND_MAX_BUF], rx[BND_MAX_BUF];

	for (size_t i = 0; i < sizeof(tx); i++) {
		tx[i] = (uint8_t)(i & 0xFFU);
	}
	int ret = bnd_xfer_compare(&cfg, tx, rx, sizeof(tx), async);

	if (ret != 0) {
		LOG_ERR("large_xfer 1024 ret=%d", ret);
		return 1;
	}
	return 0;
}

static int sc_unaligned(bool async)
{
	struct spi_config cfg = bnd_cfg(8U, BND_DEFAULT_FREQ);
	static uint8_t tx[16], rx[16];
	int fail = 0;

	for (size_t len = 1U; len < 16U; len++) {
		for (size_t i = 0; i < len; i++) {
			tx[i] = (uint8_t)((i + 1U) & 0xFFU);
		}
		int ret = bnd_xfer_compare(&cfg, tx, rx, len, async);

		if (ret != 0) {
			LOG_ERR("unaligned len=%zu ret=%d", len, ret);
			fail++;
		}
	}
	return fail;
}

static int sc_cs_toggle(bool async)
{
	struct spi_config cfg = bnd_cfg(8U, BND_DEFAULT_FREQ);
	static uint8_t tx[256], rx[256];
	static const uint8_t pat[] = {0xDE, 0xAD, 0xBE, 0xEF};
	static const size_t sizes[] = {1, 2, 4, 8, 16, 32, 64, 128, 256};
	int fail = 0;
	int ret;

	for (size_t i = 0; i < 16U; i++) {
		tx[i] = pat[i & 3U];
	}
	ret = bnd_xfer_compare(&cfg, tx, rx, 16U, async);
	if (ret != 0) {
		LOG_ERR("cs_toggle basic ret=%d", ret);
		return 1;
	}

	memset(tx, 0xA5, 8U);
	for (int i = 0; i < 50; i++) {
		ret = bnd_xfer_compare(&cfg, tx, rx, 8U, async);
		if (ret != 0) {
			fail++;
			if (fail <= 3) {
				LOG_ERR("cs_toggle iter %d ret=%d", i, ret);
			}
		}
	}

	for (size_t s = 0; s < ARRAY_SIZE(sizes); s++) {
		size_t len = sizes[s];

		for (size_t i = 0; i < len; i++) {
			tx[i] = (uint8_t)((i + s) & 0xFFU);
		}
		ret = bnd_xfer_compare(&cfg, tx, rx, len, async);
		if (ret != 0) {
			LOG_ERR("cs_toggle multi-size %zu ret=%d", len, ret);
			fail++;
		}
	}
	return fail;
}

static int sc_max_freq(bool async)
{
	struct spi_config cfg = bnd_cfg(8U,
					SPI_TEST_MAX_FREQUENCY * SPI_FREQ_MHZ);
	uint8_t tx[32], rx[32];

	for (size_t i = 0; i < sizeof(tx); i++) {
		tx[i] = (uint8_t)(0xFFU - i);
	}
	int ret = bnd_xfer_compare(&cfg, tx, rx, sizeof(tx), async);

	if (ret != 0) {
		LOG_ERR("max_freq ret=%d", ret);
		return 1;
	}
	return 0;
}

struct bnd_scenario {
	const char *name;
	int (*fn)(bool async);
};

static const struct bnd_scenario scenarios[] = {
	{ "single_byte",   sc_single_byte   },
	{ "fifo_8bit",     sc_fifo_8bit     },
	{ "fifo_16bit",    sc_fifo_16bit    },
	{ "fifo_32bit",    sc_fifo_32bit    },
	{ "fifo_flush",    sc_fifo_flush    },
	{ "xfer_sweep",    sc_xfer_sweep    },
	{ "fifo_plus_one", sc_fifo_plus_one },
	{ "large_xfer",    sc_large_xfer    },
	{ "unaligned",     sc_unaligned     },
	{ "cs_toggle",     sc_cs_toggle     },
	{ "max_freq",      sc_max_freq      },
};

static int run_boundary(bool async)
{
	int total = 0;

	for (size_t i = 0; i < ARRAY_SIZE(scenarios); i++) {
		int f = scenarios[i].fn(async);

		TC_PRINT("  %-14s : %s (%d)\n", scenarios[i].name,
			f ? "FAIL" : "OK", f);
		total += f;
	}
	return total;
}

ZTEST(test_spi_boundary, test_boundary_sync)
{
	zassert_true(spi_test_device_ready(controller_dev, "Controller"),
		     "SPI controller not ready");

	TC_PRINT("=== SPI boundary (SYNC) ===\n");
	int fail = run_boundary(false);

	zassert_equal(fail, 0, "SYNC boundary: %d scenario failure(s)", fail);
}

#if IS_ENABLED(CONFIG_SPI_ASYNC)
ZTEST(test_spi_boundary, test_boundary_async)
{
	zassert_true(spi_test_device_ready(controller_dev, "Controller"),
		     "SPI controller not ready");

	TC_PRINT("=== SPI boundary (ASYNC) ===\n");
	int fail = run_boundary(true);

	zassert_equal(fail, 0, "ASYNC boundary: %d scenario failure(s)", fail);
}
#endif /* CONFIG_SPI_ASYNC */

static void boundary_suite_before(void *fixture)
{
	test_before_func(fixture);

	k_poll_signal_init(&bnd_async_sig);
	k_poll_event_init(&bnd_async_evt, K_POLL_TYPE_SIGNAL,
			  K_POLL_MODE_NOTIFY_ONLY, &bnd_async_sig);
}

ZTEST_SUITE(test_spi_boundary, NULL, NULL, boundary_suite_before, NULL, NULL);

#endif /* CONFIG_TEST_SPI_BOUNDARY */
```

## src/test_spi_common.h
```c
/* Copyright Alif Semiconductor - All Rights Reserved.
 * Use, distribution and modification of this code is permitted under the
 * terms stated in the Alif Semiconductor Software License Agreement
 *
 * You should have received a copy of the Alif Semiconductor Software
 * License Agreement with this file. If not, please write to:
 * contact@alifsemi.com, or visit: https://alifsemi.com/license
 */

#ifndef TEST_SPI_COMMON_H_
#define TEST_SPI_COMMON_H_

#include <zephyr/logging/log.h>
#include <zephyr/ztest.h>
#include <zephyr/devicetree.h>
#include <zephyr/device.h>
#include <zephyr/drivers/spi.h>
#include <zephyr/kernel.h>
#include <zephyr/sys/util_macro.h>
#include <soc_common.h>
#include <stdbool.h>
#include <string.h>

/* ---------------------------------------------------------------------------
 * Constants
 * ---------------------------------------------------------------------------
 */
#define SPI_FREQ_MHZ                CONFIG_TEST_SPI_FREQUENCY

/* Match sample app for DMA compatibility */
#define SPI_TEST_BUFF_SIZE          200U
#define SPI_TEST_BUFF_SIZE_PERF     4096U

/* DMA-compatible word size - DMA controllers
 * typically only support 8-bit reliably
 */
#define SPI_TEST_DMA_WORD_SIZE      32U     /* Use 8-bit for DMA transfers */

/* Convenience macro to avoid repeating the long ternary in every test file */
#define SPI_TEST_WORD_SIZE \
	SPI_WORD_SET(IS_ENABLED(CONFIG_TEST_SPI_USE_DMA) ? \
		     SPI_TEST_DMA_WORD_SIZE : (uint32_t)transceive_word)

#define SPI_TEST_STACKSIZE          (1024U * 20U)
#define SPI_TEST_MAX_FREQUENCY      25U
#define SPI_TEST_NUM_TRANSFERS      1U

#define SPI_TEST_SLEEPTIME_MS       500U
#define SPI_TEST_PRIORITY_CONTROLLER    7
#define SPI_TEST_PRIORITY_TARGET        6

#define SPI_TEST_CS_DELAY_US        100U
#define SPI_TEST_TARGET_HEADSTART_US 10000U  /* Increased for DMA timing */
#define SPI_TEST_TIMEOUT_MARGIN_MS  500U

/* Devicetree node aliases */
#define SPI_CONTROLLER_NODE         DT_ALIAS(controller_spi)
#define SPI_TARGET_NODE             DT_ALIAS(target_spi)

/* DMA event router control bits */
#ifndef DMA_CTRL_ACK_TYPE_Pos
#define DMA_CTRL_ACK_TYPE_Pos       16U
#endif
#ifndef DMA_CTRL_ENA
#define DMA_CTRL_ENA                (1U << 4)
#endif
#ifndef HE_DMA_SEL_LPSPI_Pos
#define HE_DMA_SEL_LPSPI_Pos        4U
#endif
#ifndef HE_DMA_SEL_LPSPI_Msk
#define HE_DMA_SEL_LPSPI_Msk        (0x3U << HE_DMA_SEL_LPSPI_Pos)
#endif

/* ---------------------------------------------------------------------------
 * Shared data (defined in test_spi_common.c)
 * ---------------------------------------------------------------------------
 */
K_THREAD_STACK_DECLARE(controller_stack, SPI_TEST_STACKSIZE);
extern struct k_thread controller_thread_data;

K_THREAD_STACK_DECLARE(target_stack, SPI_TEST_STACKSIZE);
extern struct k_thread target_thread_data;

#if !IS_ENABLED(CONFIG_TEST_SPI_PERFORMANCE)
extern uint32_t ctrl_txdata[SPI_TEST_BUFF_SIZE];
extern uint32_t tgt_txdata[SPI_TEST_BUFF_SIZE];
extern uint32_t ctrl_rxdata[SPI_TEST_BUFF_SIZE];
extern uint32_t tgt_rxdata[SPI_TEST_BUFF_SIZE];
#else
extern uint32_t ctrl_txdata[SPI_TEST_BUFF_SIZE_PERF];
extern uint32_t ctrl_rxdata[SPI_TEST_BUFF_SIZE_PERF];
extern uint32_t tgt_txdata[SPI_TEST_BUFF_SIZE_PERF];
extern uint32_t tgt_rxdata[SPI_TEST_BUFF_SIZE_PERF];
#endif

extern atomic_t err_count;
extern atomic_val_t transceive_word;
extern uint32_t spi_test_op_flags;  /* CPOL/CPHA*/
extern atomic_t spi_test_async_mode; /* 0 = sync, 1 = async */

/* Performance error counters */
extern uint32_t ctrl_ret_tx;
extern uint32_t tgt_ret_tx;
extern uint32_t ctrl_ret_rx;
extern uint32_t tgt_ret_rx;

/* ---------------------------------------------------------------------------
 * Utility functions (test_spi_common.c)
 * ---------------------------------------------------------------------------
 */
/* Generate a pattern seed that varies with the current word size */
static inline uint16_t spi_test_pattern(uint16_t seed)
{
	return (uint16_t)(seed ^ ((uint16_t)transceive_word << 8));
}

/* 32-bit seed derived from the word-size-aware pattern */
static inline uint32_t spi_test_seed32(uint32_t base)
{
	uint16_t p = spi_test_pattern((uint16_t)base);

	return ((uint32_t)p << 16) | (uint32_t)(~p & 0xFFFFU);
}

int spi_test_prepare_data(uint32_t *data, uint16_t pattern, uint32_t count);
int spi_test_reset_buffer(uint32_t *buffer, size_t count);
bool spi_test_device_ready(const struct device *dev, const char *role);
void spi_test_controller_cs_init(struct spi_cs_control *cs);
uint64_t spi_test_transfer_timeout_ms(size_t bytes, uint32_t freq_hz);
k_timeout_t spi_test_transfer_timeout(size_t bytes, uint32_t freq_hz);

/* Inline helper: create spi_config with CS pre-configured from DT */
static inline struct spi_config spi_test_config(uint32_t operation,
						  uint32_t frequency)
{

#if DT_NODE_HAS_PROP(SPI_CONTROLLER_NODE, cs_gpios)
	struct spi_cs_control cs = {
		.gpio = GPIO_DT_SPEC_GET(SPI_CONTROLLER_NODE, cs_gpios),
		.delay = SPI_TEST_CS_DELAY_US,
	};
#else
	struct spi_cs_control cs = {0};
#endif
	return (struct spi_config){
		.frequency = frequency,
		.operation = operation,
		.slave = 0,
		.cs = cs,
	};
}
int spi_test_transceive(const struct device *dev,
			const struct spi_config *cnfg,
			const struct spi_buf_set *tx_set,
			const struct spi_buf_set *rx_set,
			bool force_reconfig);
int spi_test_transceive_async(const struct device *dev,
			      const struct spi_config *cnfg,
			      const struct spi_buf_set *tx_set,
			      const struct spi_buf_set *rx_set,
			      bool force_reconfig);
int spi_test_controller_receive_and_check(const struct device *dev,
				      const struct spi_config *cnfg,
				      const uint32_t *expected_tx,
				      uint32_t *rx_buffer,
				      size_t word_count);
void spi_test_log_first_mismatch(const uint32_t *expected,
				 const uint32_t *actual,
				 size_t word_count,
				 const char *context);

/* Ztest before-function: called by ZTEST_SUITE in each test file */
void test_before_func(void *fixture);

/* ---------------------------------------------------------------------------
 * Thread entry functions (test_spi_threads.c)
 * ---------------------------------------------------------------------------
 */

/* MOSI: controller transmit, target receive */
void controller_spi_transmit(void *p1, void *p2, void *p3);
void target_spi_receive(void *p1, void *p2, void *p3);

/* MISO: controller receive, target transmit */
void controller_receive(void *p1, void *p2, void *p3);
void target_send(void *p1, void *p2, void *p3);

/* Transceive: full-duplex controller and target */
void controller_spi(void *p1, void *p2, void *p3);
void target_spi(void *p1, void *p2, void *p3);

#endif /* TEST_SPI_COMMON_H_ */
```

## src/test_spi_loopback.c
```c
/* Copyright Alif Semiconductor - All Rights Reserved.
 * Use, distribution and modification of this code is permitted under the
 * terms stated in the Alif Semiconductor Software License Agreement
 *
 * You should have received a copy of the Alif Semiconductor Software
 * License Agreement with this file. If not, please write to:
 * contact@alifsemi.com, or visit: https://alifsemi.com/license
 */

#include <zephyr/kernel.h>
#include <zephyr/drivers/spi.h>
#include <zephyr/ztest.h>
#include <zephyr/logging/log.h>

#if IS_ENABLED(CONFIG_TEST_SPI_LOOPBACK)

#include "test_spi_common.h"

LOG_MODULE_REGISTER(spi_test_loop, LOG_LEVEL_INF);

#define LB_DEFAULT_FREQ_HZ  SPI_FREQ_MHZ
#define LB_BUF_MAX          64

/* Word-size selection: use CONFIG_TEST_SPI_WORD_SIZE */
#define LB_PINNED_WORD       CONFIG_TEST_SPI_WORD_SIZE
#define LB_WORDS             ((const uint32_t[]){LB_PINNED_WORD})

static const struct device *const controller_dev =
	DEVICE_DT_GET(SPI_CONTROLLER_NODE);

static int do_xfer(const struct spi_config *cfg,
		   const struct spi_buf_set *tx,
		   const struct spi_buf_set *rx)
{
	return spi_transceive(controller_dev, cfg, tx, rx);
}

static int xfer_compare(const struct spi_config *cfg,
			void *tx, void *rx, size_t len)
{
	struct spi_buf tb = { .buf = tx, .len = len };
	struct spi_buf rb = { .buf = rx, .len = len };
	struct spi_buf_set ts = { .buffers = &tb, .count = 1 };
	struct spi_buf_set rs = { .buffers = &rb, .count = 1 };
	int ret;

	memset(rx, 0, len);
	ret = do_xfer(cfg, &ts, &rs);
	if (ret < 0) {
		return ret;
	}
	return memcmp(tx, rx, len) == 0 ? 0 : -EIO;
}

static inline struct spi_config lb_cfg(uint32_t op_extra,
					     uint32_t word, uint32_t freq)
{
	uint32_t operation = SPI_OP_MODE_MASTER |
			     SPI_WORD_SET(word) | op_extra;

	if (IS_ENABLED(CONFIG_TEST_SPI_INTERNAL_LOOPBACK)) {
		operation |= SPI_MODE_LOOP;
	}
	return spi_test_config(operation, freq);
}


static int sc_word_sweep(void)
{
	static const uint8_t pat[] = {0xDE, 0xAD, 0xBE, 0xEF};
	static uint8_t tx[32], rx[32];
	const uint32_t *words = LB_WORDS;
	const size_t n_words = ARRAY_SIZE(LB_WORDS);
	int fail = 0;

	for (size_t i = 0; i < sizeof(tx); i++) {
		tx[i] = pat[i & 3U];
	}
	for (size_t w = 0; w < n_words; w++) {
		struct spi_config cfg = lb_cfg(0, words[w], LB_DEFAULT_FREQ_HZ);
		int ret = xfer_compare(&cfg, tx, rx, sizeof(tx));

		if (ret) {
			LOG_ERR("word_sweep w=%u ret=%d", words[w], ret);
			fail++;
		}
	}
	return fail;
}

static int sc_walking_bit(void)
{
	static const size_t sizes[] = {1, 4, 16, 64};
	static uint8_t tx[LB_BUF_MAX], rx[LB_BUF_MAX];
	struct spi_config cfg = lb_cfg(0, 8, LB_DEFAULT_FREQ_HZ);
	int fail = 0;

	for (size_t s = 0; s < ARRAY_SIZE(sizes); s++) {
		size_t len = sizes[s];

		for (size_t i = 0; i < len; i++) {
			tx[i] = (uint8_t)(1U << (i & 7U));
		}
		int ret = xfer_compare(&cfg, tx, rx, len);

		if (ret) {
			LOG_ERR("walking_bit len=%zu ret=%d", len, ret);
			fail++;
		}
	}
	return fail;
}

static int sc_cpol_cpha(void)
{
	static const uint32_t modes[] = {
		0,
		SPI_MODE_CPHA,
		SPI_MODE_CPOL,
		SPI_MODE_CPOL | SPI_MODE_CPHA,
	};
	static uint8_t tx[16], rx[16];
	int fail = 0;

	for (size_t i = 0; i < sizeof(tx); i++) {
		tx[i] = (uint8_t)(0x5A ^ i);
	}
	for (size_t m = 0; m < ARRAY_SIZE(modes); m++) {
		struct spi_config cfg = lb_cfg(modes[m], 8, LB_DEFAULT_FREQ_HZ);
		int ret = xfer_compare(&cfg, tx, rx, sizeof(tx));

		if (ret) {
			LOG_ERR("cpol_cpha mode=0x%02x ret=%d", modes[m], ret);
			fail++;
		}
	}
	return fail;
}

static int sc_tmod_tx(void)
{
	uint8_t tx[16];
	struct spi_buf tb = { .buf = tx, .len = sizeof(tx) };
	struct spi_buf_set ts = { .buffers = &tb, .count = 1 };
	struct spi_config cfg = lb_cfg(0, 8, LB_DEFAULT_FREQ_HZ);
	int ret;

	memset(tx, 0xA5, sizeof(tx));
	ret = do_xfer(&cfg, &ts, NULL);
	if (ret < 0) {
		LOG_ERR("tmod_tx ret=%d", ret);
		return 1;
	}
	return 0;
}

static int sc_config_reuse(void)
{
	static struct spi_config cfg;
	uint8_t tx[16], rx[16];
	struct spi_buf tb = { .buf = tx, .len = sizeof(tx) };
	struct spi_buf rb = { .buf = rx, .len = sizeof(rx) };
	struct spi_buf_set ts = { .buffers = &tb, .count = 1 };
	struct spi_buf_set rs = { .buffers = &rb, .count = 1 };
	int ret;

	cfg = lb_cfg(0, 8, LB_DEFAULT_FREQ_HZ);
	memset(tx, 0x5A, sizeof(tx));

	for (int pass = 0; pass < 2; pass++) {
		memset(rx, 0, sizeof(rx));
		ret = do_xfer(&cfg, &ts, &rs);
		if (ret < 0 || memcmp(tx, rx, sizeof(tx)) != 0) {
			LOG_ERR("config_reuse pass=%d ret=%d", pass, ret);
			return 1;
		}
	}
	return 0;
}

static int sc_miso_not_stuck(void)
{
	uint8_t tx[32], rx[32];
	struct spi_config cfg = lb_cfg(0, 8, LB_DEFAULT_FREQ_HZ);
	bool all_zero = true, all_ff = true;

	for (size_t i = 0; i < sizeof(tx); i++) {
		tx[i] = (uint8_t)i;
	}
	memset(rx, 0xCC, sizeof(rx));

	int ret = xfer_compare(&cfg, tx, rx, sizeof(tx));

	if (ret < 0) {
		LOG_ERR("miso_not_stuck xfer ret=%d", ret);
		return 1;
	}
	for (size_t i = 0; i < sizeof(rx); i++) {
		if (rx[i] != 0x00U) {
			all_zero = false;
		}
		if (rx[i] != 0xFFU) {
			all_ff = false;
		}
	}
	if (all_zero || all_ff) {
		LOG_ERR("MISO stuck %s", all_zero ? "LOW" : "HIGH");
		return 1;
	}
	return 0;
}

static int sc_freq_sweep(void)
{
	static const uint32_t freqs_hz[] = {
		1U  * SPI_FREQ_MHZ,
		5U  * SPI_FREQ_MHZ,
		12U * SPI_FREQ_MHZ,
		25U * SPI_FREQ_MHZ,
	};
	static uint8_t tx[32], rx[32];
	int fail = 0;

	for (size_t i = 0; i < sizeof(tx); i++) {
		tx[i] = (uint8_t)(0xC3 ^ i);
	}
	for (size_t f = 0; f < ARRAY_SIZE(freqs_hz); f++) {
		struct spi_config cfg = lb_cfg(0, 8, freqs_hz[f]);
		int ret = xfer_compare(&cfg, tx, rx, sizeof(tx));

		if (ret) {
			LOG_ERR("freq_sweep %u Hz ret=%d", freqs_hz[f], ret);
			fail++;
		}
	}
	return fail;
}

struct scenario {
	const char *name;
	int (*fn)(void);
};

static const struct scenario scenarios[] = {
	{ "word_sweep",   sc_word_sweep    },
	{ "walking_bit",  sc_walking_bit   },
	{ "cpol_cpha",    sc_cpol_cpha     },
	{ "tmod_tx",      sc_tmod_tx       },
	{ "config_reuse", sc_config_reuse  },
	{ "freq_sweep",   sc_freq_sweep    },
};

static int run_loopback(void)
{
	int total = 0;

	for (size_t i = 0; i < ARRAY_SIZE(scenarios); i++) {
		int f = scenarios[i].fn();

		TC_PRINT("  %-12s : %s (%d)\n", scenarios[i].name,
			f ? "FAIL" : "OK", f);
		total += f;
	}
	return total;
}


ZTEST(test_spi_loopback, test_loopback_sync)
{
	zassert_true(spi_test_device_ready(controller_dev, "Controller"),
		     "SPI controller not ready");

	TC_PRINT("=== SPI loopback (SYNC) ===\n");
	int fail = run_loopback();

	int wf = sc_miso_not_stuck();

	TC_PRINT("  %-12s : %s (%d)\n", "miso_wiring", wf ? "FAIL" : "OK", wf);
	fail += wf;

	zassert_equal(fail, 0, "SYNC loopback: %d scenario failure(s)", fail);
}


static void loopback_suite_before(void *fixture)
{
	test_before_func(fixture);
}

ZTEST_SUITE(test_spi_loopback, NULL, NULL, loopback_suite_before, NULL, NULL);

#endif /* CONFIG_TEST_SPI_LOOPBACK */
```

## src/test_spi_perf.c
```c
/* Copyright Alif Semiconductor - All Rights Reserved.
 * Use, distribution and modification of this code is permitted under the
 * terms stated in the Alif Semiconductor Software License Agreement
 *
 * You should have received a copy of the Alif Semiconductor Software
 * License Agreement with this file. If not, please write to:
 * contact@alifsemi.com, or visit: https://alifsemi.com/license
 */

#include <zephyr/sys/util_macro.h>

#if IS_ENABLED(CONFIG_TEST_SPI_PERFORMANCE)

#include "test_spi_threads.h"

LOG_MODULE_REGISTER(spi_test_perf, LOG_LEVEL_INF);

static void assert_mosi_perf_clean(const char *tag)
{
	zassert_equal(ctrl_ret_tx, 0U,
		      "%s: controller TX failures=%u", tag, ctrl_ret_tx);
	zassert_equal(tgt_ret_rx, 0U,
		      "%s: target RX failures=%u", tag, tgt_ret_rx);
	TC_PRINT("%s: OK\n", tag);
}

static void assert_miso_perf_clean(const char *tag)
{
	zassert_equal(tgt_ret_tx, 0U,
		      "%s: target TX failures=%u", tag, tgt_ret_tx);
	zassert_equal(ctrl_ret_rx, 0U,
		      "%s: controller RX failures=%u", tag, ctrl_ret_rx);
	TC_PRINT("%s: OK\n", tag);
}

static void assert_xcv_perf_clean(const char *tag)
{
	zassert_equal(ctrl_ret_tx, 0U,
		      "%s: controller TX failures=%u", tag, ctrl_ret_tx);
	zassert_equal(tgt_ret_tx, 0U,
		      "%s: target TX failures=%u", tag, tgt_ret_tx);
	zassert_equal(ctrl_ret_rx, 0U,
		      "%s: controller RX failures=%u", tag, ctrl_ret_rx);
	zassert_equal(tgt_ret_rx, 0U,
		      "%s: target RX failures=%u", tag, tgt_ret_rx);
	TC_PRINT("%s: OK\n", tag);
}

/* Controller TX -> Target RX */

ZTEST(test_spi_perf_mosi, test_perf_mosi)
{
	zassert_ok(spi_test_prepare_data(ctrl_txdata,
					 spi_test_pattern(0xBEEF),
					 SPI_TEST_BUFF_SIZE_PERF),
		   "Failed to prepare controller TX data");
	run_spi_test_threads(controller_spi_transmit, target_spi_receive);
	assert_mosi_perf_clean("MOSI perf");
}

ZTEST_SUITE(test_spi_perf_mosi, NULL, NULL, test_before_func, NULL, NULL);

/* Target TX -> Controller RX */

ZTEST(test_spi_perf_miso, test_perf_miso)
{
	zassert_ok(spi_test_prepare_data(tgt_txdata,
					 spi_test_pattern(0xCAFE),
					 SPI_TEST_BUFF_SIZE_PERF),
		   "Failed to prepare target TX data");
	run_spi_test_threads(controller_receive, target_send);
	assert_miso_perf_clean("MISO perf");
}

ZTEST_SUITE(test_spi_perf_miso, NULL, NULL, test_before_func, NULL, NULL);

/* Full-duplex Controller <-> Target */

ZTEST(test_spi_perf_transceive, test_perf_xcv)
{
	zassert_ok(spi_test_prepare_data(ctrl_txdata,
					 spi_test_pattern(0xBEEF),
					 SPI_TEST_BUFF_SIZE_PERF),
		   "Failed to prepare controller TX data");
	zassert_ok(spi_test_prepare_data(tgt_txdata,
					 spi_test_pattern(0xCAFE),
					 SPI_TEST_BUFF_SIZE_PERF),
		   "Failed to prepare target TX data");
	run_spi_test_threads(controller_spi, target_spi);
	assert_xcv_perf_clean("XCV perf");
}

ZTEST_SUITE(test_spi_perf_transceive, NULL, NULL, test_before_func, NULL, NULL);

#endif /* CONFIG_TEST_SPI_PERFORMANCE */
```
